VERSION ""

NS_ :

BS_:

BU_:

BO_ 152 HornSwitch: 8 Vector__XXX
	SG_ HornSwitch : 24|1@1+ (1,0) [0|1] "ON/OFF" Vector__XXX

BO_ 162 HornOperation: 8 Vector__XXX
	SG_ HornOperation : 24|1@1+ (1,0) [0|1] "ON/OFF" Vector__XXX

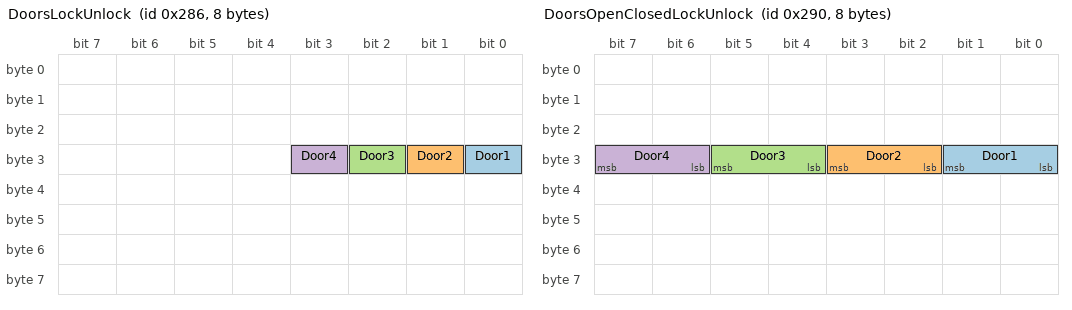
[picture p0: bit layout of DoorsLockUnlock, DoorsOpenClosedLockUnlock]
BO_ 646 DoorsLockUnlock: 8 Vector__XXX
	SG_ Door1 : 24|1@1+ (1,0) [0|1] "ON/OFF" Vector__XXX
	SG_ Door2 : 25|1@1+ (1,0) [0|1] "ON/OFF" Vector__XXX
	SG_ Door3 : 26|1@1+ (1,0) [0|1] "ON/OFF" Vector__XXX
	SG_ Door4 : 27|1@1+ (1,0) [0|1] "ON/OFF" Vector__XXX

BO_ 656 DoorsOpenClosedLockUnlock: 8 Vector__XXX
	SG_ Door1 : 24|2@1+ (1,0) [0|10] "ON/OFF" Vector__XXX
	SG_ Door2 : 26|2@1+ (1,0) [0|10] "ON/OFF" Vector__XXX
	SG_ Door3 : 28|2@1+ (1,0) [0|10] "ON/OFF" Vector__XXX
	SG_ Door4 : 30|2@1+ (1,0) [0|10] "ON/OFF" Vector__XXX

CM_ BO_ 152 "Ativa e dasativa a buzina";
CM_ SG_ 152 HornSwitch "Actual engine speed which is calculated over a minimum crankshaft angle of 720 degrees divided by the number of cylinders.â€¦";
CM_ BO_ 162 "Sinaliza o estado da buzina";
CM_ SG_ 162 HornOperation "Wheel-Based Vehicle Speed: Speed of the vehicle as calculated from wheel or tailshaft speed.";
CM_ BO_ 646 "Tranca e destranca as portas";
CM_ BO_ 656 "Sinaliza estado de abertura e trancamento das portas";
BA_DEF_ BO_  "VFrameFormat" ENUM  "StandardCAN","ExtendedCAN","reserved","J1939PG";
BA_DEF_  "DatabaseVersion" STRING ;
BA_DEF_  "BusType" STRING ;
BA_DEF_  "ProtocolType" STRING ;
BA_DEF_  "DatabaseCompiler" STRING ;
BA_DEF_DEF_  "VFrameFormat" "J1939PG";
BA_DEF_DEF_  "DatabaseVersion" "DEMO PLUS";
BA_DEF_DEF_  "BusType" "";
BA_DEF_DEF_  "ProtocolType" "";
BA_DEF_DEF_  "DatabaseCompiler" "";
BA_ "ProtocolType" "J1939";
BA_ "BusType" "CAN";
BA_ "DatabaseCompiler" "CSS ELECTRONICS (WWW.CSSELECTRONICS.COM)";
BA_ "DatabaseVersion" "1.0.0";
